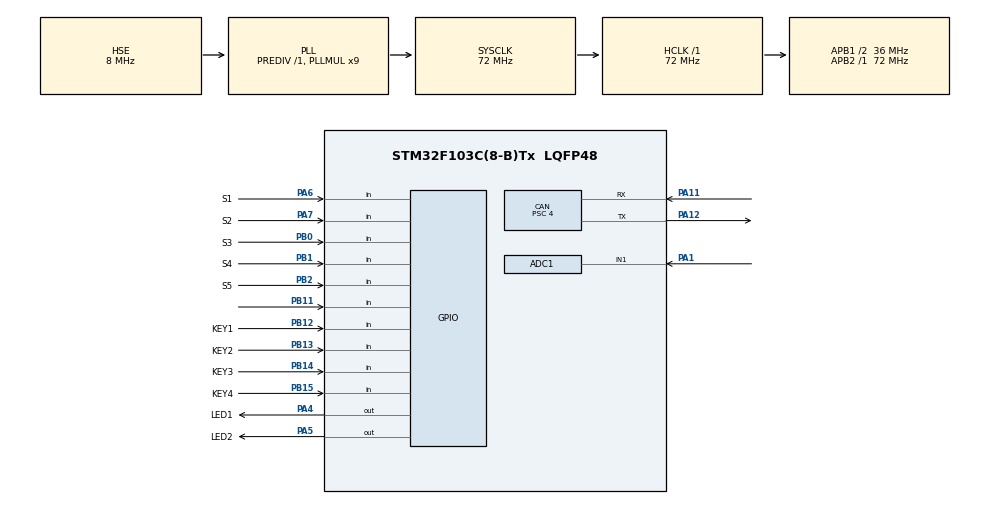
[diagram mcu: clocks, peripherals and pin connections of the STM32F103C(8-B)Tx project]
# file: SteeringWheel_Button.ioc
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ADC1.Channel-0\#ChannelRegularConversion=ADC_CHANNEL_1
ADC1.ExternalTrigConv=ADC_EXTERNALTRIGCONV_T1_CC1
ADC1.NbrOfConversionFlag=1
ADC1.Rank-0\#ChannelRegularConversion=1
ADC1.SamplingTime-0\#ChannelRegularConversion=ADC_SAMPLETIME_55CYCLES_5
ADC1.master=1
CAN.BS1=CAN_BS1_14TQ
CAN.BS2=CAN_BS2_3TQ
CAN.CalculateBaudRate=500000
CAN.CalculateTimeBit=2000
CAN.CalculateTimeQuantum=111.11111111111111
CAN.NART=ENABLE
CAN.Prescaler=4
Mcu.Family=STM32F1
Mcu.Name=STM32F103C(8-B)Tx
Mcu.Package=LQFP48
NVIC.ADC1_2_IRQn=true\:0\:0\:false\:false\:true\:true\:true\:true
NVIC.PriorityGroup=NVIC_PRIORITYGROUP_4
NVIC.TIM1_UP_IRQn=true\:0\:0\:false\:false\:true\:true\:true\:true
PA1.Signal=ADCx_IN1
PA10.Signal=USART1_RX
PA11.Mode=CAN_Activate
PA11.Signal=CAN_RX
PA12.Mode=CAN_Activate
PA12.Signal=CAN_TX
PA13.Mode=Serial_Wire
PA13.Signal=SYS_JTMS-SWDIO
PA14.Mode=Serial_Wire
PA14.Signal=SYS_JTCK-SWCLK
PA4.GPIO_Label=LED1
PA4.PinState=GPIO_PIN_SET
PA4.Signal=GPIO_Output
PA5.GPIO_Label=LED2
PA5.PinState=GPIO_PIN_SET
PA5.Signal=GPIO_Output
PA6.GPIO_Label=S1
PA6.GPIO_PuPd=GPIO_PULLUP
PA6.Signal=GPIO_Input
PA7.GPIO_Label=S2
PA7.GPIO_PuPd=GPIO_PULLUP
PA7.Signal=GPIO_Input
PA9.Signal=USART1_TX
PB0.GPIO_Label=S3
PB0.GPIO_PuPd=GPIO_PULLUP
PB0.Signal=GPIO_Input
PB1.GPIO_Label=S4
PB1.GPIO_PuPd=GPIO_PULLUP
PB1.Signal=GPIO_Input
PB11.Signal=GPIO_Input
PB12.GPIO_Label=KEY1
PB12.GPIO_PuPd=GPIO_PULLUP
PB12.Signal=GPIO_Input
PB13.GPIO_Label=KEY2
PB13.GPIO_PuPd=GPIO_PULLUP
PB13.Signal=GPIO_Input
PB14.GPIO_Label=KEY3
PB14.GPIO_PuPd=GPIO_PULLUP
PB14.Signal=GPIO_Input
PB15.GPIO_Label=KEY4
PB15.GPIO_PuPd=GPIO_PULLUP
PB15.Signal=GPIO_Input
PB2.GPIO_Label=S5
PB2.GPIO_PuPd=GPIO_PULLUP
PB2.Signal=GPIO_Input
PC14-OSC32_IN.Mode=LSE-External-Oscillator
PC14-OSC32_IN.Signal=RCC_OSC32_IN
PC15-OSC32_OUT.Mode=LSE-External-Oscillator
PC15-OSC32_OUT.Signal=RCC_OSC32_OUT
PD0-OSC_IN.Mode=HSE-External-Oscillator
PD0-OSC_IN.Signal=RCC_OSC_IN
PD1-OSC_OUT.Mode=HSE-External-Oscillator
PD1-OSC_OUT.Signal=RCC_OSC_OUT
ProjectManager.HeapSize=0x200
ProjectManager.StackSize=0x400
ProjectManager.TargetToolchain=CMake
RCC.ADCPresc=RCC_ADCPCLK2_DIV6
RCC.AHBFreq_Value=72000000
RCC.APB1CLKDivider=RCC_HCLK_DIV2
RCC.APB1Freq_Value=36000000
RCC.APB1TimFreq_Value=72000000
RCC.APB2Freq_Value=72000000
RCC.APB2TimFreq_Value=72000000
RCC.HCLKFreq_Value=72000000
RCC.PLLMUL=RCC_PLL_MUL9
RCC.PLLSourceVirtual=RCC_PLLSOURCE_HSE
RCC.SYSCLKFreq_VALUE=72000000
RCC.SYSCLKSource=RCC_SYSCLKSOURCE_PLLCLK
RCC.USBFreq_Value=72000000
SH.ADCx_IN1.0=ADC1_IN1,IN1
TIM1.Period=3999
TIM1.Prescaler=71
TIM1.TIM_MasterOutputTrigger=TIM_TRGO_UPDATE
VP_TIM1_VS_ClockSourceINT.Mode=Internal
board=custom

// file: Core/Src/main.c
/* USER CODE BEGIN Header */
/**
  ******************************************************************************
  * @file           : main.c
  * @brief          : Main program body
  ******************************************************************************
  * @attention
  *
  * Copyright (c) 2026 STMicroelectronics.
  * All rights reserved.
  *
  * This software is licensed under terms that can be found in the LICENSE file
  * in the root directory of this software component.
  * If no LICENSE file comes with this software, it is provided AS-IS.
  *
  ******************************************************************************
  */
/* USER CODE END Header */
#include "main.h"
#include "adc.h"
#include "can.h"
#include "tim.h"
#include "gpio.h"

/* USER CODE BEGIN Includes */
#include "button_panel.h"
#include "can.h"
#include "adc.h"
#include "gpio.h"
#include "tim.h"
/* USER CODE END Includes */

void SystemClock_Config(void);

int main(void)
{

  /* MCU Configuration--------------------------------------------------------*/

  /* Reset of all peripherals, Initializes the Flash interface and the Systick. */
  HAL_Init();

  /* Configure the system clock */
  SystemClock_Config();

  /* Initialize all configured peripherals */
  MX_GPIO_Init();
  MX_ADC1_Init();
  MX_CAN_Init();
  MX_TIM1_Init();
  /* USER CODE BEGIN 2 */

  /* Enable CAN receive filters (used by can.c ISR callbacks) */
  CAN_Filter_Config();

  /* Start CAN peripheral — leave init mode, join the bus */
  if (HAL_CAN_Start(&hcan) != HAL_OK) {
    Error_Handler();
  }

  /* Enable CAN RX FIFO0 message-pending interrupt */
  if (HAL_CAN_ActivateNotification(&hcan, CAN_IT_RX_FIFO0_MSG_PENDING) != HAL_OK) {
    Error_Handler();
  }

  /* Initialise steering-wheel button panel (buttons, ADC filter, CAN TX) */
  ButtonPanel_Init();

  /* USER CODE END 2 */

  /* Infinite loop */
  while (1)
  {

    /* USER CODE BEGIN 3 */

    /* Process steering-wheel button panel (10 ms scan + ADC + 50 ms CAN) */
    ButtonPanel_Process();

  }
  /* USER CODE END 3 */
}

void SystemClock_Config(void)
{
  RCC_OscInitTypeDef RCC_OscInitStruct = {0};
  RCC_ClkInitTypeDef RCC_ClkInitStruct = {0};
  RCC_PeriphCLKInitTypeDef PeriphClkInit = {0};

  /** Initializes the RCC Oscillators according to the specified parameters
  * in the RCC_OscInitTypeDef structure.
  */
  RCC_OscInitStruct.OscillatorType = RCC_OSCILLATORTYPE_HSE;
  RCC_OscInitStruct.HSEState = RCC_HSE_ON;
  RCC_OscInitStruct.HSEPredivValue = RCC_HSE_PREDIV_DIV1;
  RCC_OscInitStruct.HSIState = RCC_HSI_ON;
  RCC_OscInitStruct.PLL.PLLState = RCC_PLL_ON;
  RCC_OscInitStruct.PLL.PLLSource = RCC_PLLSOURCE_HSE;
  RCC_OscInitStruct.PLL.PLLMUL = RCC_PLL_MUL9;
  if (HAL_RCC_OscConfig(&RCC_OscInitStruct) != HAL_OK)
  {
    Error_Handler();
  }

  /** Initializes the CPU, AHB and APB buses clocks
  */
  RCC_ClkInitStruct.ClockType = RCC_CLOCKTYPE_HCLK|RCC_CLOCKTYPE_SYSCLK
                              |RCC_CLOCKTYPE_PCLK1|RCC_CLOCKTYPE_PCLK2;
  RCC_ClkInitStruct.SYSCLKSource = RCC_SYSCLKSOURCE_PLLCLK;
  RCC_ClkInitStruct.AHBCLKDivider = RCC_SYSCLK_DIV1;
  RCC_ClkInitStruct.APB1CLKDivider = RCC_HCLK_DIV2;
  RCC_ClkInitStruct.APB2CLKDivider = RCC_HCLK_DIV1;

  if (HAL_RCC_ClockConfig(&RCC_ClkInitStruct, FLASH_LATENCY_2) != HAL_OK)
  {
    Error_Handler();
  }
  PeriphClkInit.PeriphClockSelection = RCC_PERIPHCLK_ADC;
  PeriphClkInit.AdcClockSelection = RCC_ADCPCLK2_DIV6;
  if (HAL_RCCEx_PeriphCLKConfig(&PeriphClkInit) != HAL_OK)
  {
    Error_Handler();
  }
}

void Error_Handler(void)
{
  __disable_irq();
  while (1)
  {
  }
}
